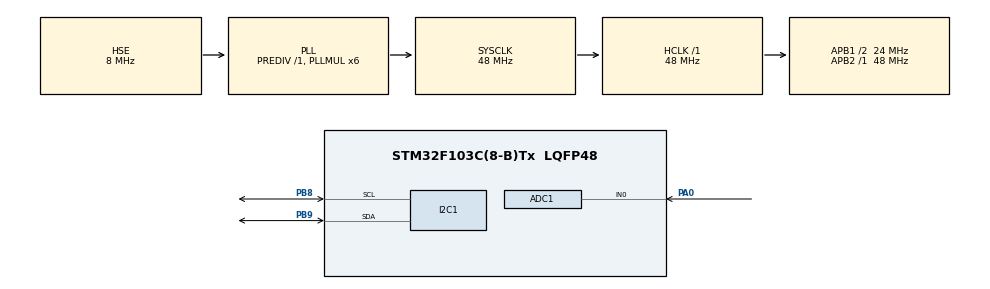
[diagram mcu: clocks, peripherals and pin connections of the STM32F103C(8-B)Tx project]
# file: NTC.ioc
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ADC1.Channel-0\#ChannelRegularConversion=ADC_CHANNEL_0
ADC1.ContinuousConvMode=ENABLE
ADC1.NbrOfConversion=1
ADC1.NbrOfConversionFlag=1
ADC1.Rank-0\#ChannelRegularConversion=1
ADC1.SamplingTime-0\#ChannelRegularConversion=ADC_SAMPLETIME_1CYCLE_5
ADC1.master=1
Dma.I2C1_TX.0.Direction=DMA_MEMORY_TO_PERIPH
Dma.I2C1_TX.0.Instance=DMA1_Channel6
Dma.I2C1_TX.0.MemDataAlignment=DMA_MDATAALIGN_BYTE
Dma.I2C1_TX.0.MemInc=DMA_MINC_ENABLE
Dma.I2C1_TX.0.Mode=DMA_NORMAL
Dma.I2C1_TX.0.PeriphDataAlignment=DMA_PDATAALIGN_BYTE
Dma.I2C1_TX.0.PeriphInc=DMA_PINC_DISABLE
Dma.I2C1_TX.0.Priority=DMA_PRIORITY_LOW
Dma.Request0=I2C1_TX
I2C1.I2C_Mode=I2C_Fast
Mcu.Family=STM32F1
Mcu.Name=STM32F103C(8-B)Tx
Mcu.Package=LQFP48
NVIC.DMA1_Channel6_IRQn=true\:0\:0\:false\:false\:true\:false\:true\:true
NVIC.I2C1_EV_IRQn=true\:0\:0\:false\:false\:true\:true\:true\:true
NVIC.PriorityGroup=NVIC_PRIORITYGROUP_4
PA0-WKUP.Signal=ADCx_IN0
PA13.Mode=Serial_Wire
PA13.Signal=SYS_JTMS-SWDIO
PA14.Mode=Serial_Wire
PA14.Signal=SYS_JTCK-SWCLK
PB8.Mode=I2C
PB8.Signal=I2C1_SCL
PB9.Mode=I2C
PB9.Signal=I2C1_SDA
PD0-OSC_IN.Mode=HSE-External-Oscillator
PD0-OSC_IN.Signal=RCC_OSC_IN
PD1-OSC_OUT.Mode=HSE-External-Oscillator
PD1-OSC_OUT.Signal=RCC_OSC_OUT
ProjectManager.HeapSize=0x200
ProjectManager.StackSize=0x400
ProjectManager.TargetToolchain=STM32CubeIDE
RCC.ADCPresc=RCC_ADCPCLK2_DIV4
RCC.AHBFreq_Value=48000000
RCC.APB1CLKDivider=RCC_HCLK_DIV2
RCC.APB1Freq_Value=24000000
RCC.APB1TimFreq_Value=48000000
RCC.APB2Freq_Value=48000000
RCC.APB2TimFreq_Value=48000000
RCC.HCLKFreq_Value=48000000
RCC.PLLMUL=RCC_PLL_MUL6
RCC.PLLSourceVirtual=RCC_PLLSOURCE_HSE
RCC.SYSCLKFreq_VALUE=48000000
RCC.SYSCLKSource=RCC_SYSCLKSOURCE_PLLCLK
RCC.USBFreq_Value=48000000
SH.ADCx_IN0.0=ADC1_IN0,IN0
board=custom

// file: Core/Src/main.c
/* USER CODE BEGIN Header */
/**
  ******************************************************************************
  * @file           : main.c
  * @brief          : Main program body
  ******************************************************************************
  * @attention
  *
  * Copyright (c) 2025 STMicroelectronics.
  * All rights reserved.
  *
  * This software is licensed under terms that can be found in the LICENSE file
  * in the root directory of this software component.
  * If no LICENSE file comes with this software, it is provided AS-IS.
  *
  ******************************************************************************
  */
/* USER CODE END Header */
#include "main.h"

/* USER CODE BEGIN Includes */
#include "math.h"
#include "Anglas_OLED_SSD1306_DMA.h"
#include "stdio.h"
/* USER CODE END Includes */

ADC_HandleTypeDef hadc1;

I2C_HandleTypeDef hi2c1;
DMA_HandleTypeDef hdma_i2c1_tx;

/* USER CODE BEGIN PV */
char buff[16];
uint16_t adc, NTC;
/* USER CODE END PV */

void SystemClock_Config(void);
static void MX_GPIO_Init(void);
static void MX_DMA_Init(void);
static void MX_ADC1_Init(void);
static void MX_I2C1_Init(void);
/* USER CODE BEGIN PFP */
uint32_t muestrasADC(uint16_t muestrasADC);
uint16_t senseTemperature();
void medirTemperatura(void);
/* USER CODE END PFP */

int main(void)
{

  /* MCU Configuration--------------------------------------------------------*/

  /* Reset of all peripherals, Initializes the Flash interface and the Systick. */
  HAL_Init();

  /* Configure the system clock */
  SystemClock_Config();

  /* Initialize all configured peripherals */
  MX_GPIO_Init();
  MX_DMA_Init();
  MX_ADC1_Init();
  MX_I2C1_Init();
  /* USER CODE BEGIN 2 */
  HAL_ADC_Start(&hadc1);
  OLED_Init_DMA();

  /* USER CODE END 2 */

  /* Infinite loop */
  /* USER CODE BEGIN WHILE */
  while (1)
  {

	  //sprintf(buff, "T:%2iC", senseTemperature());
	  //OLED_Print_Text_DMA(3,0,3,buff);

	  medirTemperatura();
    /* USER CODE END WHILE */

  }
}

void SystemClock_Config(void)
{
  RCC_OscInitTypeDef RCC_OscInitStruct = {0};
  RCC_ClkInitTypeDef RCC_ClkInitStruct = {0};
  RCC_PeriphCLKInitTypeDef PeriphClkInit = {0};

  /** Initializes the RCC Oscillators according to the specified parameters
  * in the RCC_OscInitTypeDef structure.
  */
  RCC_OscInitStruct.OscillatorType = RCC_OSCILLATORTYPE_HSE;
  RCC_OscInitStruct.HSEState = RCC_HSE_ON;
  RCC_OscInitStruct.HSEPredivValue = RCC_HSE_PREDIV_DIV1;
  RCC_OscInitStruct.HSIState = RCC_HSI_ON;
  RCC_OscInitStruct.PLL.PLLState = RCC_PLL_ON;
  RCC_OscInitStruct.PLL.PLLSource = RCC_PLLSOURCE_HSE;
  RCC_OscInitStruct.PLL.PLLMUL = RCC_PLL_MUL6;
  if (HAL_RCC_OscConfig(&RCC_OscInitStruct) != HAL_OK)
  {
    Error_Handler();
  }

  /** Initializes the CPU, AHB and APB buses clocks
  */
  RCC_ClkInitStruct.ClockType = RCC_CLOCKTYPE_HCLK|RCC_CLOCKTYPE_SYSCLK
                              |RCC_CLOCKTYPE_PCLK1|RCC_CLOCKTYPE_PCLK2;
  RCC_ClkInitStruct.SYSCLKSource = RCC_SYSCLKSOURCE_PLLCLK;
  RCC_ClkInitStruct.AHBCLKDivider = RCC_SYSCLK_DIV1;
  RCC_ClkInitStruct.APB1CLKDivider = RCC_HCLK_DIV2;
  RCC_ClkInitStruct.APB2CLKDivider = RCC_HCLK_DIV1;

  if (HAL_RCC_ClockConfig(&RCC_ClkInitStruct, FLASH_LATENCY_1) != HAL_OK)
  {
    Error_Handler();
  }
  PeriphClkInit.PeriphClockSelection = RCC_PERIPHCLK_ADC;
  PeriphClkInit.AdcClockSelection = RCC_ADCPCLK2_DIV4;
  if (HAL_RCCEx_PeriphCLKConfig(&PeriphClkInit) != HAL_OK)
  {
    Error_Handler();
  }
}

static void MX_ADC1_Init(void)
{

  ADC_ChannelConfTypeDef sConfig = {0};

  /** Common config
  */
  hadc1.Instance = ADC1;
  hadc1.Init.ScanConvMode = ADC_SCAN_DISABLE;
  hadc1.Init.ContinuousConvMode = ENABLE;
  hadc1.Init.DiscontinuousConvMode = DISABLE;
  hadc1.Init.ExternalTrigConv = ADC_SOFTWARE_START;
  hadc1.Init.DataAlign = ADC_DATAALIGN_RIGHT;
  hadc1.Init.NbrOfConversion = 1;
  if (HAL_ADC_Init(&hadc1) != HAL_OK)
  {
    Error_Handler();
  }

  /** Configure Regular Channel
  */
  sConfig.Channel = ADC_CHANNEL_0;
  sConfig.Rank = ADC_REGULAR_RANK_1;
  sConfig.SamplingTime = ADC_SAMPLETIME_1CYCLE_5;
  if (HAL_ADC_ConfigChannel(&hadc1, &sConfig) != HAL_OK)
  {
    Error_Handler();
  }

}

static void MX_I2C1_Init(void)
{

  hi2c1.Instance = I2C1;
  hi2c1.Init.ClockSpeed = 400000;
  hi2c1.Init.DutyCycle = I2C_DUTYCYCLE_2;
  hi2c1.Init.OwnAddress1 = 0;
  hi2c1.Init.AddressingMode = I2C_ADDRESSINGMODE_7BIT;
  hi2c1.Init.DualAddressMode = I2C_DUALADDRESS_DISABLE;
  hi2c1.Init.OwnAddress2 = 0;
  hi2c1.Init.GeneralCallMode = I2C_GENERALCALL_DISABLE;
  hi2c1.Init.NoStretchMode = I2C_NOSTRETCH_DISABLE;
  if (HAL_I2C_Init(&hi2c1) != HAL_OK)
  {
    Error_Handler();
  }

}

static void MX_DMA_Init(void)
{

  /* DMA controller clock enable */
  __HAL_RCC_DMA1_CLK_ENABLE();

  /* DMA interrupt init */
  /* DMA1_Channel6_IRQn interrupt configuration */
  HAL_NVIC_SetPriority(DMA1_Channel6_IRQn, 0, 0);
  HAL_NVIC_EnableIRQ(DMA1_Channel6_IRQn);

}

static void MX_GPIO_Init(void)
{

  /* GPIO Ports Clock Enable */
  __HAL_RCC_GPIOD_CLK_ENABLE();
  __HAL_RCC_GPIOA_CLK_ENABLE();
  __HAL_RCC_GPIOB_CLK_ENABLE();

}

/* USER CODE BEGIN 4 */
uint32_t muestrasADC(uint16_t muestrasADC){
	static float adcNTC;
	adcNTC=0;
    for(uint16_t i=0; i<muestrasADC; i++) adcNTC += HAL_ADC_GetValue(&hadc1);//Leo 20 muestrasADC del adc para tener una lectura mas precisa
    return adcNTC /= muestrasADC;
}

uint16_t senseTemperature(void){
	//Estoy usando un NTC de 30Kohmios y R1 debe ser el doble o un poco mas
    const float R1 = 67800;// resistencia fija del divisor de tension a GND
    static float logR2, R2, TEMPERATURA;
    //coeficientes de S-H en pagina: http://www.thinksrs.com/downloads/programs/Therm%20Calc/NTCCalibrator/NTCcalculator.html
    const float c1 = 2.095678276e-03, c2 = 0.6001278570e-04, c3 = 5.838641344e-07;
    //R2 = R1 * ((4096.0 /HAL_ADC_GetValue(&hadc1)) - 1.0);	// conversion de tension a resistencia
    R2 = R1 * ((4096.0 /muestrasADC(50)) - 1.0);	// conversion de tension a resistencia
    logR2 = log(R2);
    TEMPERATURA = (1.0 / (c1 + c2*logR2 + c3*logR2*logR2*logR2))-273.15; 	// ecuacion S-H
    return TEMPERATURA + 6;//para corregir
}

void medirTemperatura(void){
	static uint32_t adcNTC;
	static uint16_t muestras=50;
	//Estoy usando un NTC de 30Kohmios y R1 debe ser el doble o un poco mas
    const float R1 = 67800;// resistencia fija del divisor de tension a GND
    static float logR2, R2, TEMPERATURA;
    //coeficientes de S-H en pagina: http://www.thinksrs.com/downloads/programs/Therm%20Calc/NTCCalibrator/NTCcalculator.html
    const float c1 = 2.095678276e-03, c2 = 0.6001278570e-04, c3 = 5.838641344e-07;

    adcNTC=0;
    for(uint16_t i=0; i<muestras; i++) adcNTC += HAL_ADC_GetValue(&hadc1);//promedio 50 muestras de adc
    adcNTC /= muestras;
    R2 = R1 * ((4096.0 /adcNTC) - 1.0);	// conversion de tension a resistencia
    logR2 = log(R2);
    TEMPERATURA = ((1.0 / (c1 + c2*logR2 + c3*logR2*logR2*logR2))-273.15) + 6;// ecuacion S-H, +6 para calibrar
    //sprintf(buff, "T:%2.0fC", TEMPERATURA);
    //OLED_Print_Text_DMA(3,0,1,buff);

    sprintf(buff,"%3.0f|C",TEMPERATURA);
	OLED_Print_Text_DMA(2,98,1,buff);

}
/* USER CODE END 4 */

void Error_Handler(void)
{
  __disable_irq();
  while (1)
  {
  }
}
